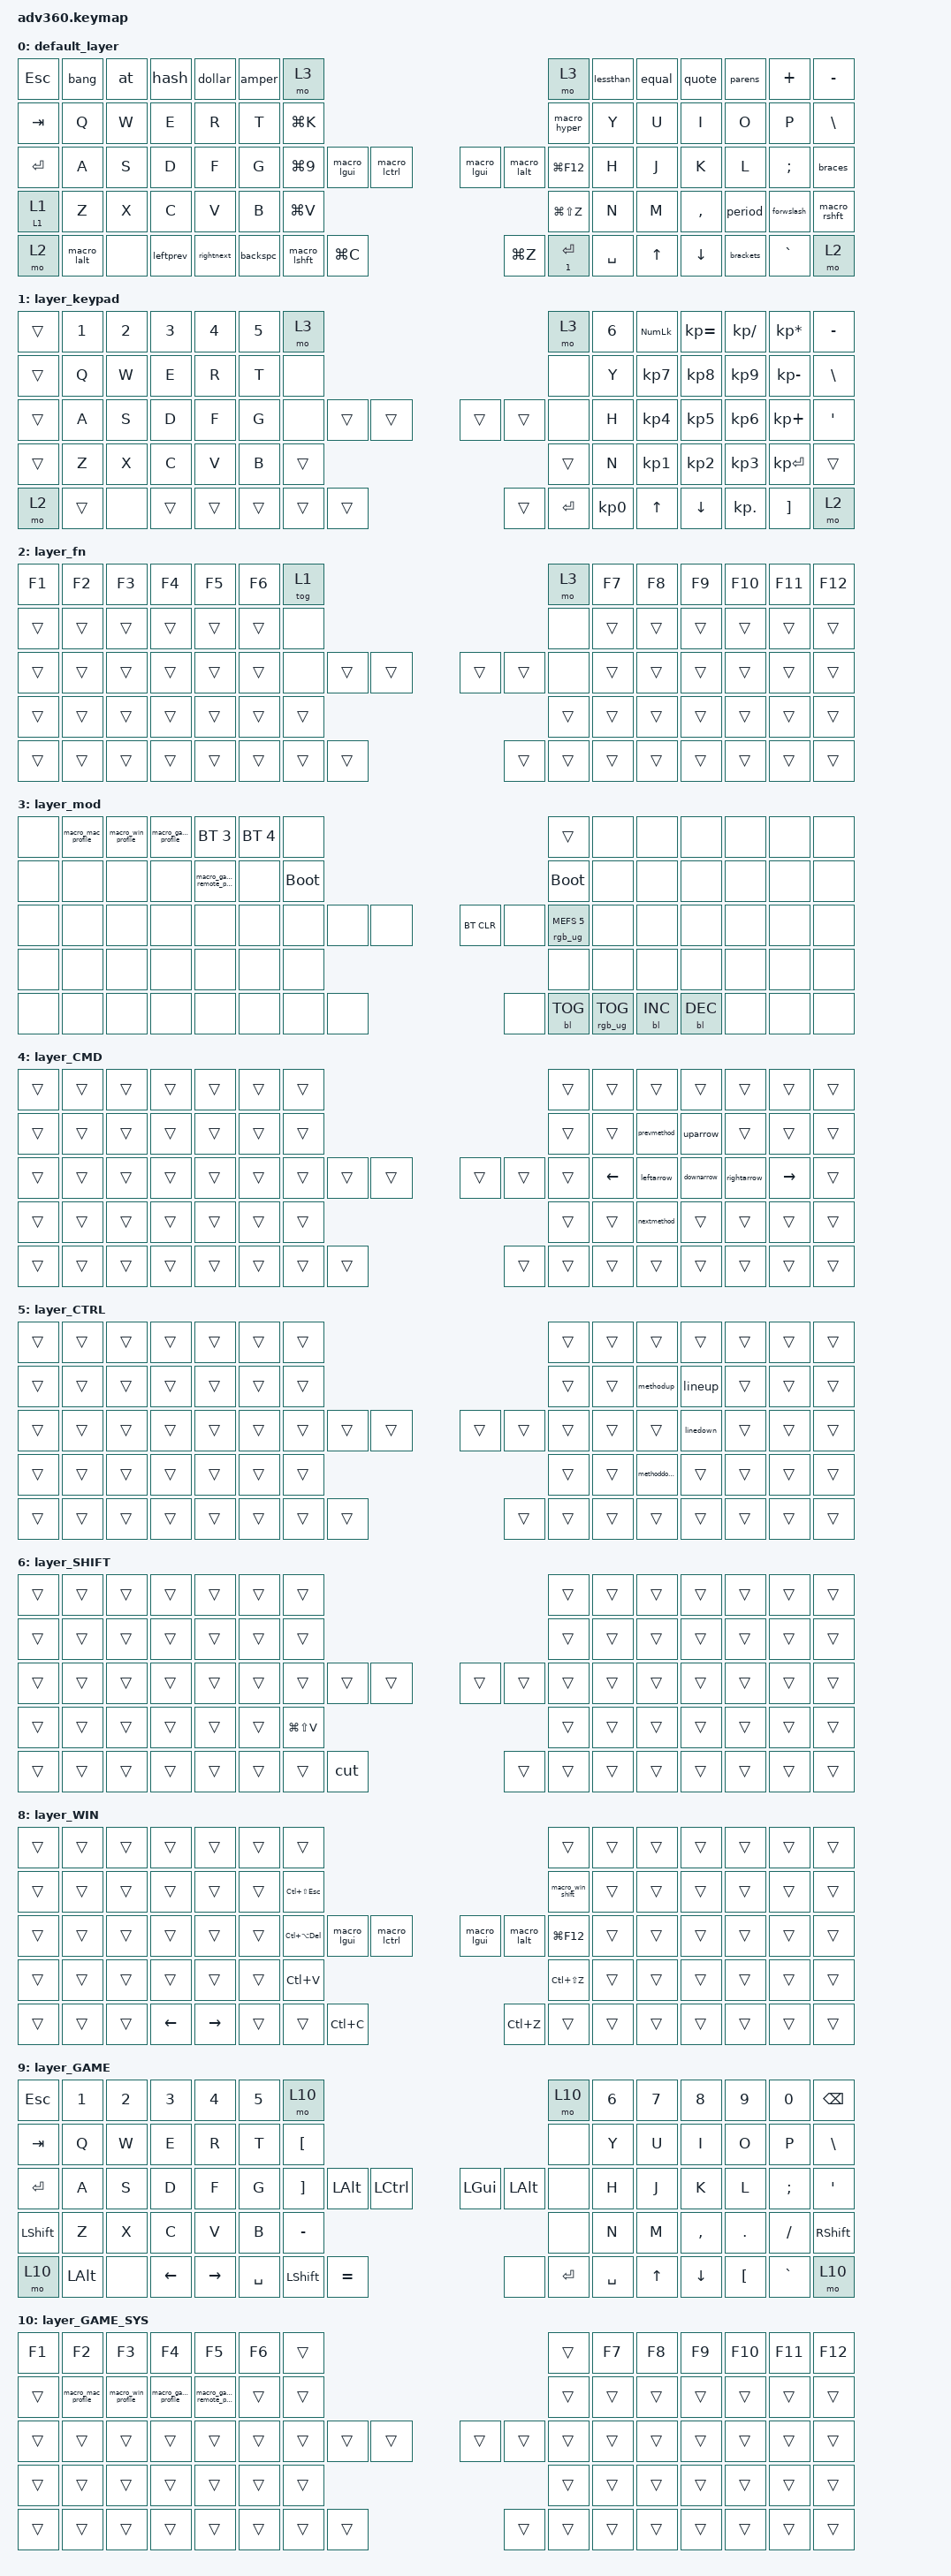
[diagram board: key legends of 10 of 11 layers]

/*
 * Copyright (c) 2020 The ZMK Contributors
 *
 * SPDX-License-Identifier: MIT
 */


/* THIS FILE WAS GENERATED!
 *
 * This file was generated automatically. You may or may not want to
 * edit it directly.
 */

#include <behaviors.dtsi>
#include <dt-bindings/zmk/keys.h>
#include <dt-bindings/zmk/bt.h>
#include <dt-bindings/zmk/rgb.h>
#include <dt-bindings/zmk/backlight.h>



/ {
  behaviors {
    #include "macros.dtsi"

    hm: homerow_mods {
        compatible = "zmk,behavior-hold-tap";
        label = "HOMEROW_MODS";
        #binding-cells = <2>;
        tapping-term-ms = <200>;
        quick_tap_ms = <175>;
        flavor = "tap-preferred";
        bindings = <&kp>, <&kp>;
    };
    bang: bang_not_equal {
        compatible = "zmk,behavior-mod-morph";
        label = "BANG_NOT_EQUAL";
        #binding-cells = <0>;
        bindings = <&kp EXCLAMATION>, <&macro_not_equal>;
        mods = <(MOD_LSFT|MOD_RSFT)>;
    };
    at: at_quest {
        compatible = "zmk,behavior-mod-morph";
        label = "AT_QUEST";
        #binding-cells = <0>;
        bindings = <&kp AT_SIGN>, <&kp QUESTION>;
        mods = <(MOD_LSFT|MOD_RSFT)>;
    };
    hash: hash_up_caret {
        compatible = "zmk,behavior-mod-morph";
        label = "HASH_UP_CARET";
        #binding-cells = <0>;
        bindings = <&kp HASH>, <&kp CARET>;
        mods = <(MOD_LSFT|MOD_RSFT)>;
    };
    dollar: dollar_expression {
        compatible = "zmk,behavior-mod-morph";
        label = "DOLLAR_EXPRESSION";
        #binding-cells = <0>;
        bindings = <&kp DOLLAR>, <&macro_expression>;
        mods = <(MOD_LSFT|MOD_RSFT)>;
    };
    amper: amper_percent {
        compatible = "zmk,behavior-mod-morph";
        label = "AMPER_PERCENT";
        #binding-cells = <0>;
        bindings = <&kp AMPERSAND>, <&kp PERCENT>;
        mods = <(MOD_LSFT|MOD_RSFT)>;
    };
    lessthan: less_than_greater_than {
        compatible = "zmk,behavior-mod-morph";
        label = "LESS_THAN_GREAT_THAN";
        #binding-cells = <0>;
        bindings = <&kp LESS_THAN>, <&kp GREATER_THAN>;
        mods = <(MOD_LSFT|MOD_RSFT)>;
    };
    equal: equal_arrow_func {
        compatible = "zmk,behavior-mod-morph";
        label = "EQUAL_ARROW_FUNC";
        #binding-cells = <0>;
        bindings = <&kp KP_EQUAL>, <&macro_arrow_func>;
        mods = <(MOD_LSFT|MOD_RSFT)>;
    };
    quote: single_quote_double_quote {
        compatible = "zmk,behavior-mod-morph";
        label = "SINGLE_QUOTE_DOUBLE_QUOTE";
        #binding-cells = <0>;
        bindings = <&kp SQT>, <&kp DQT>;
        mods = <(MOD_LSFT|MOD_RSFT)>;
    };
    parens: left_parens_right_parens {
        compatible = "zmk,behavior-mod-morph";
        label = "LEFT_PARENS_RIGHT_PARENS";
        #binding-cells = <0>;
        bindings = <&kp LPAR>, <&kp RPAR>;
        mods = <(MOD_LSFT|MOD_RSFT)>;
    };
    braces: left_brace_right_brace {
        compatible = "zmk,behavior-mod-morph";
        label = "LEFT_BRACE_RIGHT_BRACE";
        #binding-cells = <0>;
        bindings = <&kp LBRC>, <&kp RBRC>;
        mods = <(MOD_LSFT|MOD_RSFT)>;
    };
    brackets: left_bracket_right_bracke {
        compatible = "zmk,behavior-mod-morph";
        label = "LEFT_BRACKET_RIGHT_BRACKET";
        #binding-cells = <0>;
        bindings = <&kp LBKT>, <&kp RBKT>;
        mods = <(MOD_LSFT|MOD_RSFT)>;
    };
    forwslash: forw_slash_star {
        compatible = "zmk,behavior-mod-morph";
        label = "FORW_SLASH_STAR";
        #binding-cells = <0>;
        bindings = <&kp FSLH>, <&kp STAR>;
        mods = <(MOD_LSFT|MOD_RSFT)>;
    };
    period: period_underscore {
        compatible = "zmk,behavior-mod-morph";
        label = "PERIOD_UNDERSCORE";
        #binding-cells = <0>;
        bindings = <&kp PERIOD>, <&kp UNDERSCORE>;
        mods = <(MOD_LSFT|MOD_RSFT)>;
    };
    leftprev: left_arrow_prev_tab {
        compatible = "zmk,behavior-mod-morph";
        label = "LEFT_ARROW_PREV_TAB";
        #binding-cells = <0>;
        bindings = <&kp LEFT>, <&kp LG(LS(LBRC))>;
        mods = <(MOD_LGUI|MOD_RGUI)>;
    };
    rightnext: right_arrow_next_tab {
        compatible = "zmk,behavior-mod-morph";
        label = "RIGHT_ARROW_NEXT_TAB";
        #binding-cells = <0>;
        bindings = <&kp RIGHT>, <&kp LG(LS(RBRC))>;
        mods = <(MOD_LGUI|MOD_RGUI)>;
    };
    leftarrow: left_arrow {
        compatible = "zmk,behavior-mod-morph";
        label = "LEFT_ARROW";
        #binding-cells = <0>;
        bindings = <&kp LEFT>, <&kp LEFT>;
        mods = <(MOD_LGUI|MOD_RGUI)>;
    };
    rightarrow: right_arrow {
        compatible = "zmk,behavior-mod-morph";
        label = "RIGHT_ARROW";
        #binding-cells = <0>;
        bindings = <&kp RIGHT>, <&kp RIGHT>;
        mods = <(MOD_LGUI|MOD_RGUI)>;
    };
    uparrow: up_arrow {
        compatible = "zmk,behavior-mod-morph";
        label = "UP_ARROW";
        #binding-cells = <0>;
        bindings = <&kp UP>, <&kp UP>;
        mods = <(MOD_LGUI|MOD_RGUI)>;
    };
    downarrow: down_arrow {
        compatible = "zmk,behavior-mod-morph";
        label = "DOWN_ARROW";
        #binding-cells = <0>;
        bindings = <&kp DOWN>, <&kp DOWN>;
        mods = <(MOD_LGUI|MOD_RGUI)>;
    };
    backspc: backspace_delete_line {
        compatible = "zmk,behavior-mod-morph";
        label = "BACK_DELETE_LINE";
        #binding-cells = <0>;
        bindings = <&kp BSPC>, <&kp LG(BSPC)>;
        mods = <(MOD_LSFT|MOD_RSFT)>;
    };
    lineup: line-up {
        compatible = "zmk,behavior-mod-morph";
        label = "LINE_UP";
        #binding-cells = <0>;
        bindings = <&kp LA(LS(UP_ARROW))>, <&kp LA(LS(UP_ARROW))>;
        mods = <(MOD_LCTL|MOD_RCTL)>;
    };
    linedown: line-down {
        compatible = "zmk,behavior-mod-morph";
        label = "LINE_DOWN";
        #binding-cells = <0>;
        bindings = <&kp LA(LS(DOWN_ARROW))>, <&kp LA(LS(DOWN_ARROW))>;
        mods = <(MOD_LCTL|MOD_RCTL)>;
    };
    methodup: method-up {
        compatible = "zmk,behavior-mod-morph";
        label = "METHOD_UP";
        #binding-cells = <0>;
        bindings = <&kp LG(LS(UP_ARROW))>, <&kp LG(LS(UP_ARROW))>;
        mods = <(MOD_LCTL|MOD_RCTL)>;
    };
    methoddown: method-down {
        compatible = "zmk,behavior-mod-morph";
        label = "METHOD_DOWN";
        #binding-cells = <0>;
        bindings = <&kp LG(LS(DOWN_ARROW))>, <&kp LG(LS(DOWN_ARROW))>;
        mods = <(MOD_LCTL|MOD_RCTL)>;
    };
    prevmethod: prev-method {
        compatible = "zmk,behavior-mod-morph";
        label = "PREV_METHOD";
        #binding-cells = <0>;
        bindings = <&kp LC(LS(UP_ARROW))>, <&kp LC(LS(UP_ARROW))>;
        mods = <(MOD_LGUI|MOD_RGUI)>;
    };
    nextmethod: next-method {
        compatible = "zmk,behavior-mod-morph";
        label = "NEXT_METHOD";
        #binding-cells = <0>;
        bindings = <&kp LC(LS(DOWN_ARROW))>, <&kp LC(LS(DOWN_ARROW))>;
        mods = <(MOD_LGUI|MOD_RGUI)>;
    };
    cut: cut {
        compatible = "zmk,behavior-mod-morph";
        label = "CUT";
        #binding-cells = <0>;
        bindings = <&kp LG(X)>, <&kp LG(X)>;
        mods = <(MOD_LSFT|MOD_RSFT)>;
    };
    mo_tog: behavior_mo_tog {
        compatible = "zmk,behavior-hold-tap";
        label = "mo_tog";
        #binding-cells = <2>;
        flavor = "hold-preferred";
        tapping-term-ms = <200>;
        bindings = <&mo>, <&tog>;
    };
  };

    keymap {
        compatible = "zmk,keymap";


        default_layer {
            bindings = <
      &kp ESC            &bang          &at     &hash     &dollar         &amper               &mo 3                                                                              &mo 3      &lessthan        &equal          &quote               &parens   &kp PLUS       &kp MINUS
      &kp TAB            &kp Q        &kp W     &kp E       &kp R          &kp T           &kp LG(K)                                                                       &macro_hyper          &kp Y         &kp U           &kp I                 &kp O      &kp P        &kp BSLH
    &kp ENTER            &kp A        &kp S     &kp D       &kp F          &kp G          &kp LG(N9)  &macro_lgui  &macro_lctrl                    &macro_lgui  &macro_lalt &kp LG(F12)          &kp H         &kp J           &kp K                 &kp L   &kp SEMI         &braces
  &mo_tog 1 1            &kp Z        &kp X     &kp C       &kp V          &kp B                                      &kp LG(V)                  &kp LG(LS(Z))                                   &kp N         &kp M       &kp COMMA               &period &forwslash    &macro_rshft
        &mo 2      &macro_lalt        &none &leftprev  &rightnext                           &backspc &macro_lshft     &kp LG(C)                      &kp LG(Z)  &mt 1 ENTER   &kp SPACE                       &kp UP        &kp DOWN             &brackets  &kp GRAVE           &mo 2
            >;
        };

        layer_keypad {
            bindings = <
    &trans  &kp N1  &kp N2    &kp N3     &kp N4  &kp N5               &mo 3                                                                &mo 3  &kp N6  &kp KP_NUM  &kp KP_EQUAL  &kp KP_DIVIDE  &kp KP_MULTIPLY  &kp MINUS
    &trans   &kp Q   &kp W     &kp E      &kp R   &kp T               &none                                                                &none   &kp Y   &kp KP_N7     &kp KP_N8      &kp KP_N9     &kp KP_MINUS   &kp BSLH
    &trans   &kp A   &kp S     &kp D      &kp F   &kp G               &none     &trans    &trans                    &trans     &trans      &none   &kp H   &kp KP_N4     &kp KP_N5      &kp KP_N6      &kp KP_PLUS    &kp SQT
    &trans   &kp Z   &kp X     &kp C      &kp V   &kp B                                   &trans                    &trans                         &kp N   &kp KP_N1     &kp KP_N2      &kp KP_N3     &kp KP_ENTER     &trans
     &mo 2  &trans   &none    &trans     &trans                      &trans     &trans    &trans                    &trans  &kp ENTER  &kp KP_N0              &kp UP      &kp DOWN     &kp KP_DOT         &kp RBKT      &mo 2
            >;
        };

        layer_fn {
            bindings = <
 &kp F1  &kp F2  &kp F3  &kp F4  &kp F5  &kp F6            &tog 1                                                            &mo 3  &kp F7  &kp F8  &kp F9  &kp F10  &kp F11  &kp F12
 &trans  &trans  &trans  &trans  &trans  &trans             &none                                                            &none  &trans  &trans  &trans   &trans   &trans   &trans
 &trans  &trans  &trans  &trans  &trans  &trans             &none  &trans           &trans                  &trans  &trans   &none  &trans  &trans  &trans   &trans   &trans   &trans
 &trans  &trans  &trans  &trans  &trans  &trans                                     &trans                  &trans                  &trans  &trans  &trans   &trans   &trans   &trans
 &trans  &trans  &trans  &trans  &trans                    &trans  &trans           &trans                  &trans  &trans  &trans          &trans  &trans   &trans   &trans   &trans
            >;
        };

        layer_mod {
            bindings = <
  &none  &macro_mac_profile  &macro_win_profile  &macro_game_profile  &bt BT_SEL 3  &bt BT_SEL 4                  &none                                                                          &trans   &none       &none       &none   &none   &none   &none
  &none               &none               &none                &none         &macro_game_remote_profile         &none            &bootloader                                                                     &bootloader   &none       &none       &none   &none   &none   &none
  &none               &none               &none                &none         &none         &none                  &none   &none   &none                  &bt BT_CLR       &none  &rgb_ug RGB_MEFS_CMD 5   &none       &none       &none   &none   &none   &none
  &none               &none               &none                &none         &none         &none                                  &none                       &none                                       &none       &none       &none   &none   &none   &none
  &none               &none               &none                &none         &none                                &none   &none   &none                       &none  &bl BL_TOG         &rgb_ug RGB_TOG          &bl BL_INC  &bl BL_DEC   &none   &none   &none
            >;
        };

        layer_CMD {
            bindings = <
 &trans  &trans  &trans                  &trans                   &trans  &trans            &trans                                                  &trans         &trans                  &trans          &trans           &trans           &trans  &trans
 &trans  &trans  &trans                  &trans                   &trans  &trans            &trans                                                  &trans         &trans             &prevmethod        &uparrow           &trans           &trans  &trans
 &trans  &trans  &trans                  &trans                   &trans  &trans            &trans  &trans  &trans                  &trans  &trans  &trans &kp LEFT_ARROW              &leftarrow      &downarrow      &rightarrow  &kp RIGHT_ARROW  &trans
 &trans  &trans  &trans                  &trans                   &trans  &trans                            &trans                  &trans                         &trans             &nextmethod          &trans           &trans           &trans  &trans
 &trans  &trans  &trans                  &trans                   &trans                    &trans  &trans  &trans                  &trans  &trans  &trans                                 &trans          &trans           &trans           &trans  &trans
            >;
        };

        layer_CTRL {
            bindings = <
 &trans  &trans  &trans  &trans  &trans  &trans            &trans                                                  &trans  &trans                  &trans                  &trans  &trans  &trans  &trans
 &trans  &trans  &trans  &trans  &trans  &trans            &trans                                                  &trans  &trans               &methodup                 &lineup  &trans  &trans  &trans
 &trans  &trans  &trans  &trans  &trans  &trans            &trans  &trans  &trans                  &trans  &trans  &trans  &trans                  &trans               &linedown  &trans  &trans  &trans
 &trans  &trans  &trans  &trans  &trans  &trans                            &trans                  &trans                  &trans             &methoddown                  &trans  &trans  &trans  &trans
 &trans  &trans  &trans  &trans  &trans                    &trans  &trans  &trans                  &trans  &trans  &trans                          &trans                  &trans  &trans  &trans  &trans
            >;
        };

        layer_SHIFT {
            bindings = <
 &trans  &trans  &trans  &trans  &trans  &trans                       &trans                                                                    &trans  &trans  &trans  &trans  &trans  &trans  &trans
 &trans  &trans  &trans  &trans  &trans  &trans                       &trans                                                                    &trans  &trans  &trans  &trans  &trans  &trans  &trans
 &trans  &trans  &trans  &trans  &trans  &trans                       &trans             &trans         &trans                  &trans  &trans  &trans  &trans  &trans  &trans  &trans  &trans  &trans
 &trans  &trans  &trans  &trans  &trans  &trans                                                  &kp LG(LS(V))                  &trans                  &trans  &trans  &trans  &trans  &trans  &trans
 &trans  &trans  &trans  &trans  &trans                               &trans             &trans           &cut                  &trans  &trans  &trans          &trans  &trans  &trans  &trans  &trans
            >;
        };

        layer_LALT {
            bindings = <
 &trans  &trans  &trans  &trans  &trans  &trans                       &trans                                                                    &trans  &trans  &trans  &trans  &trans  &trans  &trans
 &trans  &trans  &trans  &trans  &trans  &trans                       &trans                                                                    &trans  &trans  &trans  &trans  &trans  &trans  &trans
 &trans  &trans  &trans  &trans  &trans  &trans                       &trans             &trans         &trans                  &trans  &trans  &trans  &trans  &trans  &trans  &trans  &trans  &trans
 &trans  &trans  &trans  &trans  &trans  &trans                                              &kp LG(LS(LA(V)))                  &trans                  &trans  &trans  &trans  &trans  &trans  &trans
&trans  &trans  &trans  &trans  &trans                                &trans             &trans         &trans                  &trans  &trans  &trans          &trans  &trans  &trans  &trans  &trans
            >;
        };

        layer_WIN {
            bindings = <
 &trans  &trans  &trans    &trans     &trans  &trans            &trans                                                                       &trans  &trans                  &trans                  &trans  &trans  &trans  &trans
 &trans  &trans  &trans    &trans     &trans  &trans   &kp LC(LS(ESC))                                                             &macro_win_shift  &trans                  &trans                  &trans  &trans  &trans  &trans
 &trans  &trans  &trans    &trans     &trans  &trans   &kp LC(LA(DEL))   &macro_lgui &macro_lctrl             &macro_lgui  &macro_lalt  &kp LG(F12)  &trans                  &trans                  &trans  &trans  &trans  &trans
 &trans  &trans  &trans    &trans     &trans  &trans                                    &kp LC(V)           &kp LC(LS(Z))                            &trans                  &trans                  &trans  &trans  &trans  &trans
 &trans  &trans  &trans  &kp LEFT  &kp RIGHT                    &trans        &trans    &kp LC(C)               &kp LC(Z)       &trans       &trans                          &trans                  &trans  &trans  &trans  &trans
            >;
        };

        layer_GAME {
            bindings = <
   &kp ESC  &kp N1  &kp N2    &kp N3     &kp N4  &kp N5    &mo 10                                                   &mo 10  &kp N6  &kp N7   &kp N8  &kp N9    &kp N0  &kp BSPC
   &kp TAB   &kp Q   &kp W     &kp E      &kp R   &kp T  &kp LBKT                                                    &none   &kp Y   &kp U    &kp I   &kp O     &kp P  &kp BSLH
 &kp ENTER   &kp A   &kp S     &kp D      &kp F   &kp G  &kp RBKT  &kp LALT  &kp LCTRL       &kp LGUI  &kp LALT      &none   &kp H   &kp J    &kp K   &kp L  &kp SEMI   &kp SQT
 &kp LSHFT   &kp Z   &kp X     &kp C      &kp V   &kp B                     &kp MINUS          &none                         &kp N   &kp M &kp COMMA &kp DOT &kp FSLH &kp RSHFT
    &mo 10 &kp LALT  &none  &kp LEFT  &kp RIGHT         &kp SPACE &kp LSHFT  &kp EQUAL          &none &kp ENTER  &kp SPACE         &kp UP &kp DOWN &kp LBKT &kp GRAVE    &mo 10
            >;
        };

        /* Sits above layer_GAME, which would otherwise shadow &mo 2 and &mo 3. */
        layer_GAME_SYS {
            bindings = <
    &kp F1              &kp F2              &kp F3               &kp F4                      &kp F5  &kp F6  &trans                                  &trans  &kp F7  &kp F8  &kp F9  &kp F10  &kp F11  &kp F12
    &trans  &macro_mac_profile  &macro_win_profile  &macro_game_profile  &macro_game_remote_profile  &trans  &trans                                  &trans  &trans  &trans  &trans   &trans   &trans   &trans
    &trans              &trans              &trans               &trans                      &trans  &trans  &trans  &trans  &trans  &trans  &trans  &trans  &trans  &trans  &trans   &trans   &trans   &trans
    &trans              &trans              &trans               &trans                      &trans  &trans                  &trans  &trans                  &trans  &trans  &trans   &trans   &trans   &trans
    &trans              &trans              &trans               &trans                      &trans          &trans  &trans  &trans  &trans  &trans  &trans          &trans  &trans   &trans   &trans   &trans
            >;
        };
    };
};
